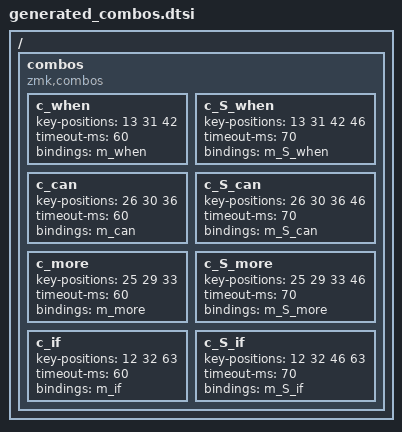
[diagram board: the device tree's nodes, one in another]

/*
 * Generated ZMK Combos from chords/jocke_chords.json
 * Automatically included by glove80.keymap
 * DO NOT EDIT MANUALLY
 */

/ {
    combos {
        compatible = "zmk,combos";

        // Combo for word: when (Chord: ehw)
        c_when: c_when {
            key-positions = <13 31 42>;
            timeout-ms = <60>; /* Timeout based on key count */
            bindings = <&m_when>;
            // layers = <LAYER_Base>; // Optional: restrict to specific layers
        };
        // Shifted combo for word: when
        c_S_when: c_S_when {
            key-positions = <13 31 42 46>;
            timeout-ms = <70>; /* Timeout based on key count */
            bindings = <&m_S_when>;
            // layers = <LAYER_Base>; // Optional: restrict to specific layers
        };
        // Combo for word: can (Chord: acn)
        c_can: c_can {
            key-positions = <26 30 36>;
            timeout-ms = <60>; /* Timeout based on key count */
            bindings = <&m_can>;
            // layers = <LAYER_Base>; // Optional: restrict to specific layers
        };
        // Shifted combo for word: can
        c_S_can: c_S_can {
            key-positions = <26 30 36 46>;
            timeout-ms = <70>; /* Timeout based on key count */
            bindings = <&m_S_can>;
            // layers = <LAYER_Base>; // Optional: restrict to specific layers
        };
        // Combo for word: more (Chord: mor)
        c_more: c_more {
            key-positions = <25 29 33>;
            timeout-ms = <60>; /* Timeout based on key count */
            bindings = <&m_more>;
            // layers = <LAYER_Base>; // Optional: restrict to specific layers
        };
        // Shifted combo for word: more
        c_S_more: c_S_more {
            key-positions = <25 29 33 46>;
            timeout-ms = <70>; /* Timeout based on key count */
            bindings = <&m_S_more>;
            // layers = <LAYER_Base>; // Optional: restrict to specific layers
        };
        // Combo for word: if (Chord: fi)
        c_if: c_if {
            key-positions = <12 32 63>;
            timeout-ms = <60>; /* Timeout based on key count */
            bindings = <&m_if>;
            // layers = <LAYER_Base>; // Optional: restrict to specific layers
        };
        // Shifted combo for word: if
        c_S_if: c_S_if {
            key-positions = <12 32 46 63>;
            timeout-ms = <70>; /* Timeout based on key count */
            bindings = <&m_S_if>;
            // layers = <LAYER_Base>; // Optional: restrict to specific layers
        };
    }; // end of combos
}; // end of /
